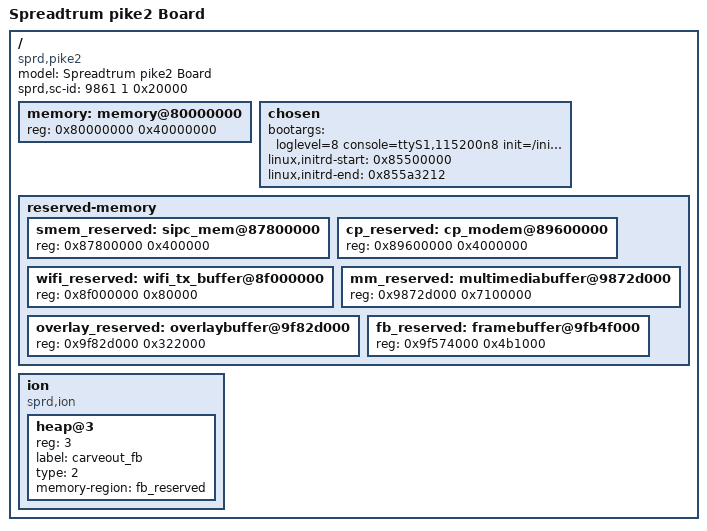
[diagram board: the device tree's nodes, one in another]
/*
 * Spreadtrum SC9833 FPGA board DTS file
 *
 * Copyright (C) 2015-2016, Spreadtrum Communications Inc.
 *
 * This file is licensed under a dual GPLv2 or X11 license.
 */

/dts-v1/;

/ {
	model = "Spreadtrum pike2 Board";

	compatible = "sprd,pike2";

	sprd,sc-id = <9861 1 0x20000>;

	memory: memory@80000000 {
		device_type = "memory";
		reg = <0x80000000 0x40000000>;
	};

	chosen {
		bootargs = "loglevel=8 console=ttyS1,115200n8 init=/init root=/dev/ram0 rw androidboot.hardware=pike2";
		linux,initrd-start = <0x85500000>;
		linux,initrd-end = <0x855a3212>;
	};

	reserved-memory {
		#address-cells = <1>;
		#size-cells = <1>;
		ranges;

		smem_reserved: sipc_mem@87800000 {
			reg = <0x87800000 0x400000>;
		};

		cp_reserved: cp_modem@89600000 {
			reg = <0x89600000 0x4000000>;
		};

		wifi_reserved: wifi_tx_buffer@8f000000 {
			reg = <0x8f000000 0x80000>;
		};

		mm_reserved: multimediabuffer@9872d000{
			reg = <0x9872d000 0x7100000>;
		};

		overlay_reserved: overlaybuffer@9f82d000{
			reg = <0x9f82d000 0x322000>;
		};

		fb_reserved: framebuffer@9fb4f000{
			reg = <0x9f574000 0x4b1000>;
		};
	};

	ion {
		compatible = "sprd,ion";
		#address-cells = <1>;
                #size-cells = <0>;
		heap@3 {
			reg = <3>;
			label = "carveout_fb";
			type = <2>;
			memory-region = <&fb_reserved>;
		};
	};
};
